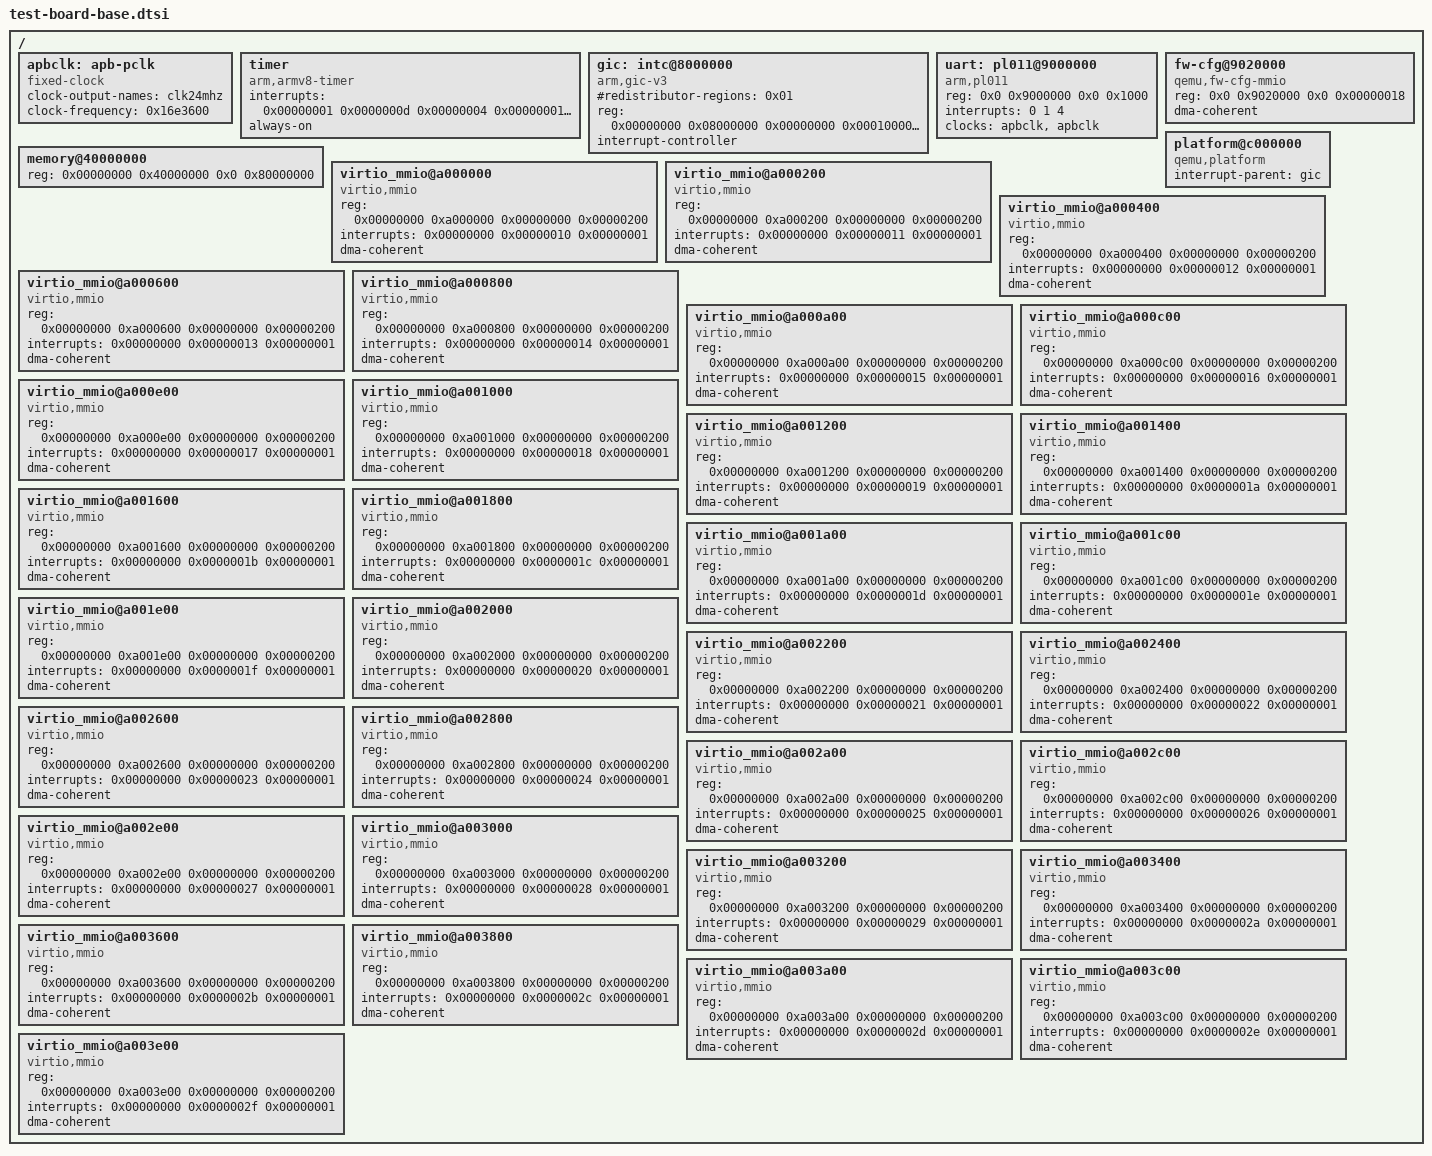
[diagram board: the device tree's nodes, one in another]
// SPDX-License-Identifier: GPL-2.0

/ {
	/*
	 *  Devices shared by all Juno boards
	 */
	apbclk: apb-pclk {
		clock-output-names = "clk24mhz";
		clock-frequency = <0x16e3600>;
		#clock-cells = <0x00>;
		compatible = "fixed-clock";
	};

	timer {
		compatible = "arm,armv8-timer";
		interrupts = <0x00000001 0x0000000d 0x00000004
					  0x00000001 0x0000000e 0x00000004
					  0x00000001 0x0000000b 0x00000004
					  0x00000001 0x0000000a 0x00000004>;
		always-on;
	};

	gic: intc@8000000 {
		compatible = "arm,gic-v3";
		#interrupt-cells = <0x00000003>;
		#address-cells = <0x00000002>;
		#size-cells = <0x00000002>;
		#redistributor-regions = <0x01>;
		reg = <0x00000000 0x08000000 0x00000000 0x00010000 0x00000000 0x080A0000 0x00000000 0x00F60000>;
		interrupt-controller;
		ranges;
	};
	
	uart: pl011@9000000 {
		compatible = "arm,pl011", "arm,primecell";
		reg = <0x0 0x9000000 0x0 0x1000>;
		interrupts = <0 1 4>;
		clocks = <&apbclk>, <&apbclk>;
		clock-names = "uartclk\0apb_pclk";
	};

	memory@40000000 {
		device_type = "memory";
		reg = <0x00000000 0x40000000 0x0 0x80000000>;
	};

	fw-cfg@9020000 {
		compatible = "qemu,fw-cfg-mmio";
		reg = <0x0 0x9020000 0x0 0x00000018>;
		dma-coherent;
	};

	platform@c000000 {
		compatible = "qemu,platform\0simple-bus";
		#address-cells = <0x00000001>;
		#size-cells = <0x00000001>;
		interrupt-parent = <&gic>;
		ranges = <0x00 0x00 0xc000000 0x2000000>;
	};

	virtio_mmio@a000000 {
		compatible = "virtio,mmio";
		reg = <0x00000000 0xa000000 0x00000000 0x00000200>;
		interrupts = <0x00000000 0x00000010 0x00000001>;
		dma-coherent;
	};
	
	virtio_mmio@a000200 {
		compatible = "virtio,mmio";
		reg = <0x00000000 0xa000200 0x00000000 0x00000200>;
		interrupts = <0x00000000 0x00000011 0x00000001>;
		dma-coherent;
	};
	
	virtio_mmio@a000400 {
		compatible = "virtio,mmio";
		reg = <0x00000000 0xa000400 0x00000000 0x00000200>;
		interrupts = <0x00000000 0x00000012 0x00000001>;
		dma-coherent;
	};
	
	virtio_mmio@a000600 {
		compatible = "virtio,mmio";
		reg = <0x00000000 0xa000600 0x00000000 0x00000200>;
		interrupts = <0x00000000 0x00000013 0x00000001>;
		dma-coherent;
	};
	
	virtio_mmio@a000800 {
		compatible = "virtio,mmio";
		reg = <0x00000000 0xa000800 0x00000000 0x00000200>;
		interrupts = <0x00000000 0x00000014 0x00000001>;
		dma-coherent;
	};
	
	virtio_mmio@a000a00 {
		compatible = "virtio,mmio";
		reg = <0x00000000 0xa000a00 0x00000000 0x00000200>;
		interrupts = <0x00000000 0x00000015 0x00000001>;
		dma-coherent;
	};
	
	virtio_mmio@a000c00 {
		compatible = "virtio,mmio";
		reg = <0x00000000 0xa000c00 0x00000000 0x00000200>;
		interrupts = <0x00000000 0x00000016 0x00000001>;
		dma-coherent;
	};
	
	virtio_mmio@a000e00 {
		compatible = "virtio,mmio";
		reg = <0x00000000 0xa000e00 0x00000000 0x00000200>;
		interrupts = <0x00000000 0x00000017 0x00000001>;
		dma-coherent;
	};
	
	virtio_mmio@a001000 {
		compatible = "virtio,mmio";
		reg = <0x00000000 0xa001000 0x00000000 0x00000200>;
		interrupts = <0x00000000 0x00000018 0x00000001>;
		dma-coherent;
	};
	
	virtio_mmio@a001200 {
		compatible = "virtio,mmio";
		reg = <0x00000000 0xa001200 0x00000000 0x00000200>;
		interrupts = <0x00000000 0x00000019 0x00000001>;
		dma-coherent;
	};
	
	virtio_mmio@a001400 {
		compatible = "virtio,mmio";
		reg = <0x00000000 0xa001400 0x00000000 0x00000200>;
		interrupts = <0x00000000 0x0000001a 0x00000001>;
		dma-coherent;
	};
	
	virtio_mmio@a001600 {
		compatible = "virtio,mmio";
		reg = <0x00000000 0xa001600 0x00000000 0x00000200>;
		interrupts = <0x00000000 0x0000001b 0x00000001>;
		dma-coherent;
	};
	
	virtio_mmio@a001800 {
		compatible = "virtio,mmio";
		reg = <0x00000000 0xa001800 0x00000000 0x00000200>;
		interrupts = <0x00000000 0x0000001c 0x00000001>;
		dma-coherent;
	};
	
	virtio_mmio@a001a00 {
		compatible = "virtio,mmio";
		reg = <0x00000000 0xa001a00 0x00000000 0x00000200>;
		interrupts = <0x00000000 0x0000001d 0x00000001>;
		dma-coherent;
	};
	
	virtio_mmio@a001c00 {
		compatible = "virtio,mmio";
		reg = <0x00000000 0xa001c00 0x00000000 0x00000200>;
		interrupts = <0x00000000 0x0000001e 0x00000001>;
		dma-coherent;
	};
	
	virtio_mmio@a001e00 {
		compatible = "virtio,mmio";
		reg = <0x00000000 0xa001e00 0x00000000 0x00000200>;
		interrupts = <0x00000000 0x0000001f 0x00000001>;
		dma-coherent;
	};
	
	virtio_mmio@a002000 {
		compatible = "virtio,mmio";
		reg = <0x00000000 0xa002000 0x00000000 0x00000200>;
		interrupts = <0x00000000 0x00000020 0x00000001>;
		dma-coherent;
	};
	
	virtio_mmio@a002200 {
		compatible = "virtio,mmio";
		reg = <0x00000000 0xa002200 0x00000000 0x00000200>;
		interrupts = <0x00000000 0x00000021 0x00000001>;
		dma-coherent;
	};
	
	virtio_mmio@a002400 {
		compatible = "virtio,mmio";
		reg = <0x00000000 0xa002400 0x00000000 0x00000200>;
		interrupts = <0x00000000 0x00000022 0x00000001>;
		dma-coherent;
	};
	
	virtio_mmio@a002600 {
		compatible = "virtio,mmio";
		reg = <0x00000000 0xa002600 0x00000000 0x00000200>;
		interrupts = <0x00000000 0x00000023 0x00000001>;
		dma-coherent;
	};
	
	virtio_mmio@a002800 {
		compatible = "virtio,mmio";
		reg = <0x00000000 0xa002800 0x00000000 0x00000200>;
		interrupts = <0x00000000 0x00000024 0x00000001>;
		dma-coherent;
	};
	
	virtio_mmio@a002a00 {
		compatible = "virtio,mmio";
		reg = <0x00000000 0xa002a00 0x00000000 0x00000200>;
		interrupts = <0x00000000 0x00000025 0x00000001>;
		dma-coherent;
	};
	
	virtio_mmio@a002c00 {
		compatible = "virtio,mmio";
		reg = <0x00000000 0xa002c00 0x00000000 0x00000200>;
		interrupts = <0x00000000 0x00000026 0x00000001>;
		dma-coherent;
	};
	
	virtio_mmio@a002e00 {
		compatible = "virtio,mmio";
		reg = <0x00000000 0xa002e00 0x00000000 0x00000200>;
		interrupts = <0x00000000 0x00000027 0x00000001>;
		dma-coherent;
	};
	
	virtio_mmio@a003000 {
		compatible = "virtio,mmio";
		reg = <0x00000000 0xa003000 0x00000000 0x00000200>;
		interrupts = <0x00000000 0x00000028 0x00000001>;
		dma-coherent;
	};
	
	virtio_mmio@a003200 {
		compatible = "virtio,mmio";
		reg = <0x00000000 0xa003200 0x00000000 0x00000200>;
		interrupts = <0x00000000 0x00000029 0x00000001>;
		dma-coherent;
	};
	
	virtio_mmio@a003400 {
		compatible = "virtio,mmio";
		reg = <0x00000000 0xa003400 0x00000000 0x00000200>;
		interrupts = <0x00000000 0x0000002a 0x00000001>;
		dma-coherent;
	};
	
	virtio_mmio@a003600 {
		compatible = "virtio,mmio";
		reg = <0x00000000 0xa003600 0x00000000 0x00000200>;
		interrupts = <0x00000000 0x0000002b 0x00000001>;
		dma-coherent;
	};
	
	virtio_mmio@a003800 {
		compatible = "virtio,mmio";
		reg = <0x00000000 0xa003800 0x00000000 0x00000200>;
		interrupts = <0x00000000 0x0000002c 0x00000001>;
		dma-coherent;
	};
	
	virtio_mmio@a003a00 {
		compatible = "virtio,mmio";
		reg = <0x00000000 0xa003a00 0x00000000 0x00000200>;
		interrupts = <0x00000000 0x0000002d 0x00000001>;
		dma-coherent;
	};
	
	virtio_mmio@a003c00 {
		compatible = "virtio,mmio";
		reg = <0x00000000 0xa003c00 0x00000000 0x00000200>;
		interrupts = <0x00000000 0x0000002e 0x00000001>;
		dma-coherent;
	};
	
	virtio_mmio@a003e00 {
		compatible = "virtio,mmio";
		reg = <0x00000000 0xa003e00 0x00000000 0x00000200>;
		interrupts = <0x00000000 0x0000002f 0x00000001>;
		dma-coherent;
	};
};
